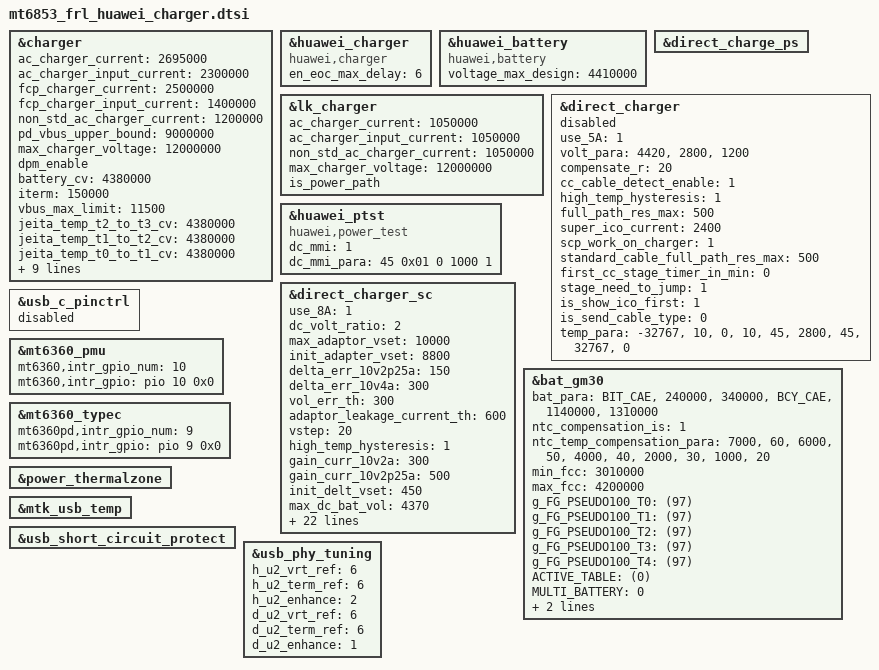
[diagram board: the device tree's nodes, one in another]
&charger {
	ac_charger_current = <2695000>;
	ac_charger_input_current = <2300000>;
	fcp_charger_current = <2500000>;
	fcp_charger_input_current = <1400000>;
	non_std_ac_charger_current = <1200000>;
	pd_vbus_upper_bound = <9000000>;
	max_charger_voltage = <12000000>;
	dpm_enable;
	battery_cv = <4380000>;
	iterm = <150000>;
	vbus_max_limit = <11500>;
	jeita_temp_t2_to_t3_cv = <4380000>;
	jeita_temp_t1_to_t2_cv = <4380000>;
	jeita_temp_t0_to_t1_cv = <4380000>;
	jeita_temp_t3_to_t4_cur = <1435000>;
	jeita_temp_t2_to_t3_cur = <2870000>;
	jeita_temp_t1_to_t2_cur = <1230000>;
	jeita_temp_t0_to_t1_cur = <410000>;
	temp_t3_thres_minus_x_degree = <44>;
	vdpm_buf_limit = <100>;
	vdpm_para =
			"-32767", "4000", "4300", "50",
			"4000", "4200", "4500", "50",
			"4200", "32767", "4600", "50";
	charge_full_design = <4200000>;
};

&huawei_charger {
	compatible = "huawei,charger";
	en_eoc_max_delay = <6>;
	status = "okay";
};

&huawei_battery {
	compatible = "huawei,battery";
	voltage_max_design = <4410000>;
	status = "okay";
};

&lk_charger{
	ac_charger_current = <1050000>;
	ac_charger_input_current = <1050000>;
	non_std_ac_charger_current = <1050000>;
	max_charger_voltage = <12000000>;
	is_power_path;
};

&direct_charge_ps {
	status = "ok";
};

&direct_charger {
	use_5A = <1>;
	volt_para =
		"4420", "2800", "1200";
	compensate_r = <20>;
	cc_cable_detect_enable = <1>;
	high_temp_hysteresis = <1>;
	full_path_res_max = <500>;
	super_ico_current = <2400>;
	scp_work_on_charger = <1>;
	standard_cable_full_path_res_max = <500>;
	first_cc_stage_timer_in_min = <0>;
	stage_need_to_jump = "1";
	is_show_ico_first = <1>;
	is_send_cable_type = <0>;
	temp_para =
		"-32767", "10", "0",
		"10", "45", "2800",
		"45", "32767", "0";
	status = "disable";
};

&huawei_ptst {
	compatible = "huawei,power_test";
	dc_mmi = <1>;
	dc_mmi_para = <45 0x01 0 1000 1>;
	status = "ok";
};

&direct_charger_sc {
	use_8A = <1>;
	dc_volt_ratio = <2>;
	max_adaptor_vset = <10000>;
	init_adapter_vset = <8800>;
	delta_err_10v2p25a = <150>;
	delta_err_10v4a = <300>;
	vol_err_th = <300>;
	adaptor_leakage_current_th = <600>;
	vstep = <20>;
	high_temp_hysteresis = <1>;
	gain_curr_10v2a = <300>;
	gain_curr_10v2p25a = <500>;
	init_delt_vset = <450>;
	max_dc_bat_vol = <4370>;
	max_current_for_none_standard_cable = <6000>;
	adaptor_antifake_check_enable = <1>;
	adaptor_antifake_key_index = <2>;
	ui_max_pwr = <40000>;
	volt_para =
		"4200", "8000", "6000",
		"4330", "6000", "5460",
		"4350", "5460", "4200",
		"4400", "4200", "1200";
	compensate_r = <8>;
	cc_cable_detect_enable = <1>;
	full_path_res_max = <500>;
	scp_work_on_charger = <1>;
	standard_cable_full_path_res_max = <500>;
	first_cc_stage_timer_in_min = <10>;
	stage_need_to_jump = "-1";
	is_show_ico_first = <1>;
	is_send_cable_type = <0>;
	temp_para =
		"-32767", "10", "0",
		"10", "45", "8000",
		"45", "32767", "0";
	resist_para =
		"0", "300", "6000",
		"300", "500", "4000";
	std_resist_para =
		"0", "300", "8000",
		"300", "500", "4000";
	10v2p25a_cur_para =
		"-32767", "5500",  "2000",
		"5500",   "9000",  "2500",
		"9000",   "10000", "2250",
		"10000",  "10500", "2000",
		"10500",  "32767", "1500";
	status = "ok";
};

&bat_gm30 {
	bat_para =
		"BIT_CAE", "240000", "340000",
		"BCY_CAE", "1140000", "1310000";
	ntc_compensation_is = <1>;
	ntc_temp_compensation_para =
		"7000", "60",
		"6000", "50",
		"4000", "40",
		"2000", "30",
		"1000", "20";
	min_fcc = <3010000>;
	max_fcc = <4200000>;
	g_FG_PSEUDO100_T0 = <(97)>;
	g_FG_PSEUDO100_T1 = <(97)>;
	g_FG_PSEUDO100_T2 = <(97)>;
	g_FG_PSEUDO100_T3 = <(97)>;
	g_FG_PSEUDO100_T4 = <(97)>;
	ACTIVE_TABLE = <(0)>;
	MULTI_BATTERY = <0>;
	dlpt_optimization;
	CAR_TUNE_VALUE = <(97)>;
	#include "BIT_CAE_4v40_4200mah_40w_ext.dtsi"
	#include "BCY_CAE_4v40_4200mah_40w_ext.dtsi"
};

&usb_c_pinctrl {
	status = "disabled";
};

&mt6360_pmu {
	mt6360,intr_gpio_num = <10>; /* direct defined GPIO num */
	mt6360,intr_gpio = <&pio 10 0x0>;
};

&mt6360_typec {
	mt6360pd,intr_gpio_num = <9>; /* direct defined GPIO num */
	mt6360pd,intr_gpio = <&pio 9 0x0>;
};

&power_thermalzone {
	status = "ok";
};

&mtk_usb_temp {
	status = "ok";
};

&usb_short_circuit_protect {
	status = "ok";
};

&usb_phy_tuning {
	h_u2_vrt_ref = <6>;
	h_u2_term_ref = <6>;
	h_u2_enhance = <2>;
	d_u2_vrt_ref = <6>;
	d_u2_term_ref = <6>;
	d_u2_enhance = <1>;
	status = "ok";
};
